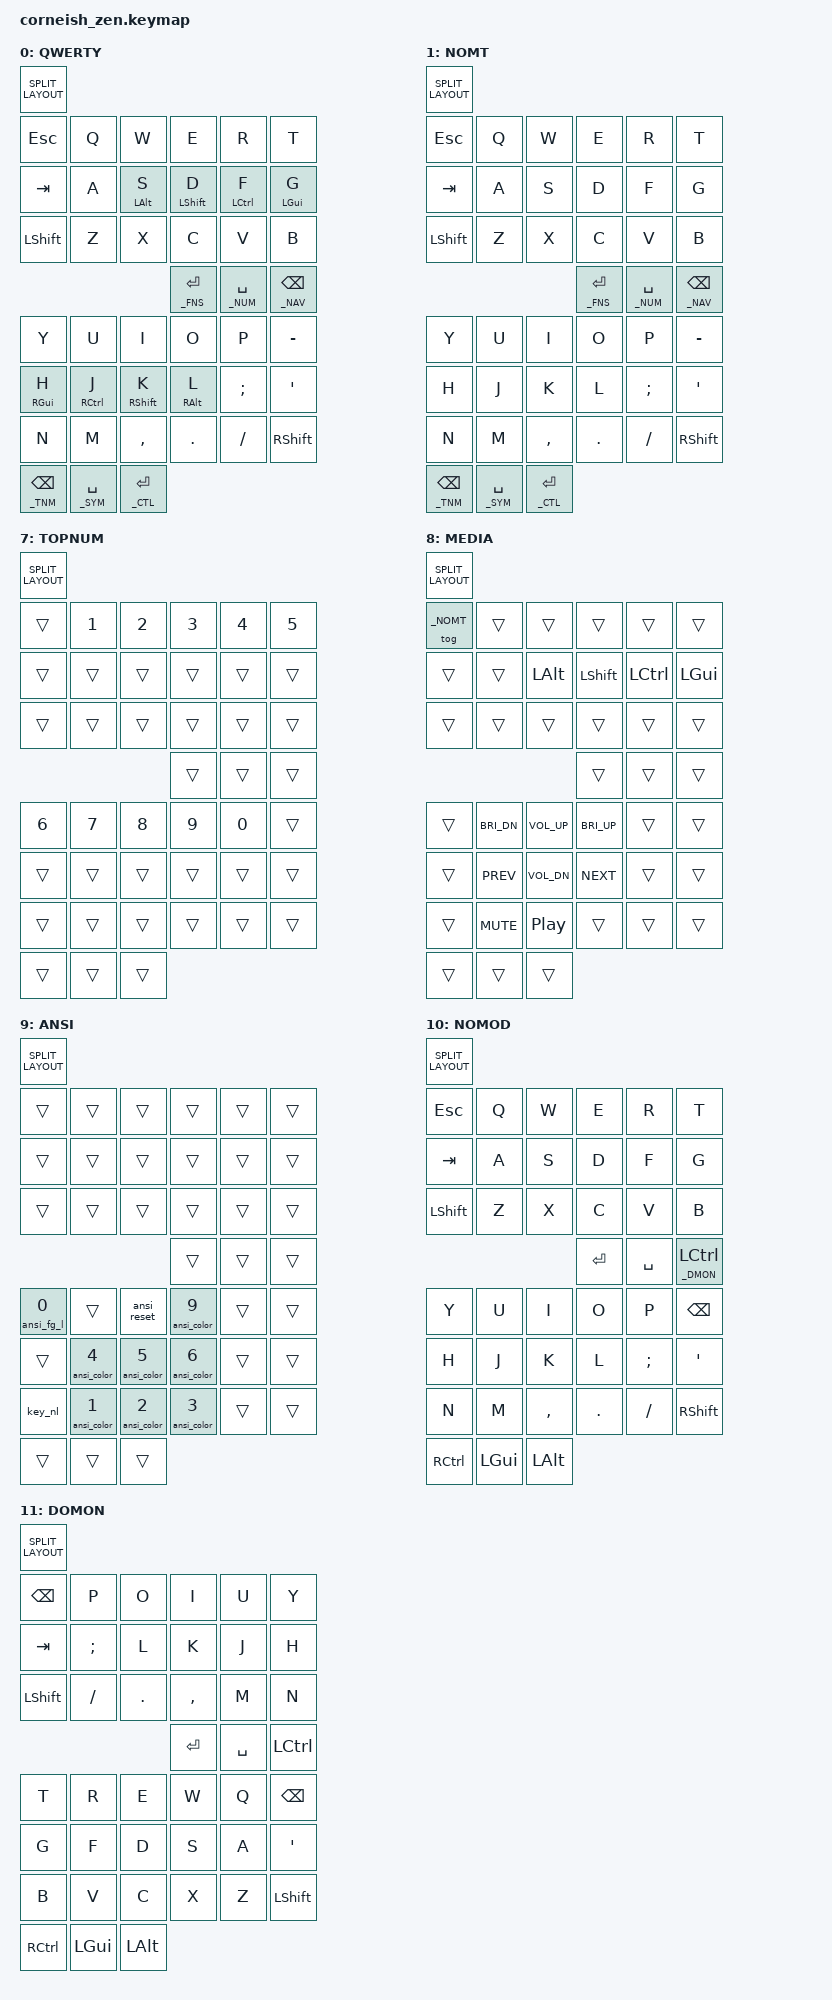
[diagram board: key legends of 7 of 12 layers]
#include <behaviors.dtsi>
#include <dt-bindings/zmk/keys.h>
#include <dt-bindings/zmk/bt.h>
#include <dt-bindings/zmk/outputs.h>

#define _BASE 0
#define _NOMT 1
#define _SYM  2
#define _NUM  3
#define _NAV  4
#define _FNS  5
#define _CTL  6
#define _TNM  7
#define _MED  8
#define _ANSI 9
#define _NOMD 10
#define _DMON 11


#define SPLIT_LAYOUT( \
        K00,    K01,    K02,    K03,    K04,    K05, \
        K06,    K07,    K08,    K09,    K10,    K11, \
        K12,    K13,    K14,    K15,    K16,    K17, \
                                K18,    K19,    K20, \
        \
        K21,    K22,    K23,    K24,    K25,    K26, \
        K27,    K28,    K29,    K30,    K31,    K32, \
        K33,    K34,    K35,    K36,    K37,    K38, \
        K39,    K40,    K41 \
) \
K00  K01  K02  K03  K04  K05    K21  K22  K23  K24  K25  K26 \
K06  K07  K08  K09  K10  K11    K27  K28  K29  K30  K31  K32 \
K12  K13  K14  K15  K16  K17    K33  K34  K35  K36  K37  K38 \
               K18  K19  K20    K39  K40  K41


#define LEFT_LAYER( \
        K00,    K01,    K02,    K03,    K04,    K05, \
        K06,    K07,    K08,    K09,    K10,    K11, \
        K12,    K13,    K14,    K15,    K16,    K17, \
                                K18,    K19,    K20 \
) \
K00  K01  K02  K03  K04  K05    &trans  &trans  &trans  &trans  &trans  &trans \
K06  K07  K08  K09  K10  K11    &trans  &trans  &trans  &trans  &trans  &trans \
K12  K13  K14  K15  K16  K17    &trans  &trans  &trans  &trans  &trans  &trans \
               K18  K19  K20    &trans  &trans  &trans

#define RIGHT_LAYER( \
        K21,    K22,    K23,    K24,    K25,    K26, \
        K27,    K28,    K29,    K30,    K31,    K32, \
        K33,    K34,    K35,    K36,    K37,    K38, \
        K39,    K40,    K41 \
) \
&trans  &trans  &trans  &trans  &trans  &trans    K21  K22  K23  K24  K25  K26 \
&trans  &trans  &trans  &trans  &trans  &trans    K27  K28  K29  K30  K31  K32 \
&trans  &trans  &trans  &trans  &trans  &trans    K33  K34  K35  K36  K37  K38 \
                        &trans  &trans  &trans    K39  K40  K41


#define MIRYOKU_SHIFT_FUNCTION(NAME, BINDING, SHIFT_BINDING) \
/ { \
  behaviors { \
    NAME: NAME { \
      compatible = "zmk,behavior-mod-morph"; \
      label = U_STRINGIFY(NAME); \
      #binding-cells = <0>; \
      bindings = <BINDING>, <SHIFT_BINDING>; \
      mods = <(MOD_LSFT|MOD_RSFT)>; \
    }; \
  }; \
};

&caps_word { continue-list = <UNDERSCORE MINUS BACKSPACE>; };
&lt { quick-tap-ms = <200>; };

/ {
  chosen {
    zmk,matrix_transform = &default_transform;
    //zmk,matrix_transform = &five_column_transform;
  };
};

/ {
        behaviors {
             hm: homerow_mods {
                compatible = "zmk,behavior-hold-tap";
                label = "HOMEROW_MODS";
                #binding-cells = <2>;
                tapping-term-ms = <150>;
                quick-tap-ms = <200>;
                flavor = "balanced";
                require-prior-idle-ms = <50>;
                bindings = <&kp>, <&kp>;
             };

             u_bt_sel_0: u_bt_sel_0 {
                compatible = "zmk,behavior-mod-morph";
                label = "u_bt_sel_0";
                #binding-cells = <0>;
                bindings = <&bt BT_SEL 0>, <&bt BT_DISC 0>;
                mods = <(MOD_LSFT|MOD_RSFT)>;
             };

             u_bt_sel_1: u_bt_sel_1 {
                compatible = "zmk,behavior-mod-morph";
                label = "u_bt_sel_1";
                #binding-cells = <0>;
                bindings = <&bt BT_SEL 1>, <&bt BT_DISC 1>;
                mods = <(MOD_LSFT|MOD_RSFT)>;
             };

             u_bt_sel_2: u_bt_sel_2 {
                compatible = "zmk,behavior-mod-morph";
                label = "u_bt_sel_2";
                #binding-cells = <0>;
                bindings = <&bt BT_SEL 2>, <&bt BT_DISC 2>;
                mods = <(MOD_LSFT|MOD_RSFT)>;
             };

             u_bt_sel_3: u_bt_sel_3 {
                compatible = "zmk,behavior-mod-morph";
                label = "u_bt_sel_3";
                #binding-cells = <0>;
                bindings = <&bt BT_SEL 3>, <&bt BT_DISC 3>;
                mods = <(MOD_LSFT|MOD_RSFT)>;
             };

             u_bt_sel_4: u_bt_sel_4 {
                compatible = "zmk,behavior-mod-morph";
                label = "u_bt_sel_4";
                #binding-cells = <0>;
                bindings = <&bt BT_SEL 4>, <&bt BT_DISC 4>;
                mods = <(MOD_LSFT|MOD_RSFT)>;
             };

             ansi_color: ansi_color {
                compatible = "zmk,behavior-macro-one-param";
                #binding-cells = <1>;
                bindings
                        = <&kp BSLH &kp E &kp LBKT &kp N3>
                        , <&macro_param_1to1>
                        , <&kp MACRO_PLACEHOLDER>
                        , <&kp M>;
             };

             ansi_fg_l: ansi_fg_l {
                compatible = "zmk,behavior-macro-one-param";
                #binding-cells = <1>;
                bindings
                        = <&kp BSLH &kp E &kp LBKT &kp N9>
                        , <&macro_param_1to1>
                        , <&kp MACRO_PLACEHOLDER>
                        , <&kp M>;
             };

             key_nl: key_nl {
                compatible = "zmk,behavior-macro";
                #binding-cells = <0>;
                bindings = <&kp BSLH &kp N>;
             };

             ansi_reset: ansi_reset {
                compatible = "zmk,behavior-macro";
                #binding-cells = <0>;
                bindings = <&kp BSLH &kp E &kp LBKT &kp M>;
             };
        };

        combos {
                compatible = "zmk,combos";
                combo_double_shift_caps_word {
                        timeout-ms = <200>;
                        key-positions = <24 35>;
                        bindings = <&caps_word>;
                };

                combo_toggle_no_home_row_mods {
                        timeout-ms = <200>;
                        key-positions = <0 11>;
                        bindings = <&tog _NOMD>;
                };
        };

        macros {
                ZMK_MACRO(emoji,
                        wait-ms = <30>;
                        tap-ms = <40>;
                        bindings
                                = <&macro_press   &kp LCTRL>
                                , <&macro_press   &kp LGUI>
                                , <&macro_tap     &kp SPACE>
                                , <&macro_release &kp LGUI>
                                , <&macro_release &kp LCTRL>
                                ;
                )
        };

        conditional_layers {
                compatible = "zmk,conditional-layers";
                tri_layer {
                        if-layers = <_NAV _TNM>;
                        then-layer = <_MED>;
                };

                ansi_layer {
                        if-layers = <_NUM _SYM>;
                        then-layer = <_ANSI>;
                };
        };

        keymap {
                compatible = "zmk,keymap";

                default_layer {
                        label = "QWERTY";

                        bindings = < SPLIT_LAYOUT(
  &kp ESC,        &kp Q,          &kp W,          &kp E,          &kp R,          &kp T,
  &kp TAB,   &kp A,          &hm LALT S,     &hm LSHFT D,    &hm LCTRL F,    &hm LGUI G,
  &kp LSHFT,      &kp Z,          &kp X,          &kp C,          &kp V,          &kp B,
                                                  &lt _FNS RET,   &lt _NUM SPACE, &lt _NAV BSPC,

  &kp Y,          &kp U,          &kp I,          &kp O,          &kp P,          &kp MINUS,
  &hm RGUI H,     &hm RCTRL J,    &hm RSHFT K,    &hm RALT L,     &kp SEMI,       &kp SQT,
  &kp N,          &kp M,          &kp COMMA,      &kp DOT,        &kp FSLH,       &kp RSHFT,
  &lt _TNM BSPC,  &lt _SYM SPACE, &lt _CTL RET
                        ) >;
                };

                nomt_layer {
                        label = "NOMT";

                        bindings = < SPLIT_LAYOUT(
  &kp ESC,        &kp Q,          &kp W,          &kp E,          &kp R,          &kp T,
  &kp TAB,   &kp A,          &kp S,     &kp D,    &kp F,    &kp G,
  &kp LSHFT,      &kp Z,          &kp X,          &kp C,          &kp V,          &kp B,
                                                  &lt _FNS RET,   &lt _NUM SPACE, &lt _NAV BSPC,

  &kp Y,          &kp U,          &kp I,          &kp O,          &kp P,          &kp MINUS,
  &kp H,     &kp J,    &kp K,    &kp L,     &kp SEMI,       &kp SQT,
  &kp N,          &kp M,          &kp COMMA,      &kp DOT,        &kp FSLH,       &kp RSHFT,
  &lt _TNM BSPC,  &lt _SYM SPACE, &lt _CTL RET
                        ) >;
                };

                symbol_layer {
                       label = "SYMBOL";

                        bindings = < LEFT_LAYER(
  &kp AMPS,       &kp EXCL,       &kp AT,         &kp LBRC,       &kp RBRC,       &kp PIPE,
  &kp BSLH,       &kp HASH,       &kp DLLR,       &kp LPAR,       &kp RPAR,       &kp GRAVE,
  &trans,         &kp PRCNT,      &kp CARET,      &kp LBKT,       &kp RBKT,       &kp TILDE,
                                                  &trans,         &trans,         &trans
                        ) >;
                };

                numpad_layer {
                        label = "NUMPAD";

                        bindings = < RIGHT_LAYER(
  &kp KP_DIVIDE,  &kp KP_N7,      &kp KP_N8,      &kp KP_N9,      &kp KP_MULTIPLY,&trans,
  &kp KP_EQUAL,   &kp KP_N4,      &kp KP_N5,      &kp KP_N6,      &kp KP_PLUS,    &trans,
  &kp KP_MINUS,   &kp KP_N1,      &kp KP_N2,      &kp KP_N3,      &kp BSLH,       &trans,
  &trans,         &kp KP_N0,      &kp KP_DOT
                        ) >;
                };

                nav_layer {
                        label = "NAV";

                        bindings = < RIGHT_LAYER(
  &kp PG_UP,      &kp HOME,       &kp UP,         &kp END,        &trans,         &kp DEL,
  &kp PG_DN,      &kp LEFT,       &kp DOWN,       &kp RIGHT,      &trans,         &trans,
  &trans,         &trans,         &trans,         &trans,         &trans,         &emoji,
  &trans,         &trans,         &trans
                        ) >;
                };

                fns_layer {
                        label = "FNS";

                        bindings = < RIGHT_LAYER(
  &kp PG_UP,      &kp F7,         &kp F8,         &kp F9,         &kp F11,        &trans,
  &kp PG_DN,      &kp F4,         &kp F5,         &kp F6,         &kp F11,        &trans,
  &trans,         &kp F1,         &kp F2,         &kp F3,         &kp F10,        &trans,
  &trans,         &trans,         &trans
                        ) >;
                };

                control_layer {
                       label = "CONTROL";

                       bindings = < LEFT_LAYER(
  &trans,         &trans,         &trans,         &trans,         &out OUT_TOG,   &bt BT_CLR,
  &trans,         &u_bt_sel_0,    &u_bt_sel_1,    &u_bt_sel_2,    &u_bt_sel_3,    &u_bt_sel_4,
  &trans,         &trans,         &trans,         &trans,         &trans,         &trans,
                                                  &trans,         &trans,         &trans
                        ) >;
                };

                topnum_layer {
                       label = "TOPNUM";

                       bindings = < SPLIT_LAYOUT(
  &trans,         &kp N1,         &kp N2,         &kp N3,         &kp N4,         &kp N5,
  &trans,         &trans,         &trans,         &trans,         &trans,         &trans,
  &trans,         &trans,         &trans,         &trans,         &trans,         &trans,
                                                  &trans,         &trans,         &trans,

  &kp N6,         &kp N7,         &kp N8,         &kp N9,         &kp N0,         &trans,
  &trans,         &trans,         &trans,         &trans,         &trans,         &trans,
  &trans,         &trans,         &trans,         &trans,         &trans,         &trans,
  &trans,         &trans,         &trans
                        ) >;
                };

                media_layer {
                       label = "MEDIA";

                       bindings = < SPLIT_LAYOUT(
  &tog _NOMT,         &trans,         &trans,         &trans,         &trans,         &trans,
  &trans,         &trans,         &kp LALT,         &kp LSHFT,         &kp LCTRL,         &kp LGUI,
  &trans,         &trans,         &trans,         &trans,         &trans,         &trans,
                                                  &trans,         &trans,         &trans,

  &trans,         &kp C_BRI_DN,   &kp C_VOL_UP,   &kp C_BRI_UP,   &trans,         &trans,
  &trans,         &kp C_PREV,     &kp C_VOL_DN,   &kp C_NEXT,     &trans,         &trans,
  &trans,         &kp K_MUTE,     &kp C_PP,       &trans,         &trans,         &trans,
  &trans,         &trans,         &trans
                        ) >;
                };

                ansi_layer {
                       label = "ANSI";

                       bindings = < SPLIT_LAYOUT(
  &trans,         &trans,         &trans,         &trans,         &trans,         &trans,
  &trans,         &trans,         &trans,         &trans,         &trans,         &trans,
  &trans,         &trans,         &trans,         &trans,         &trans,         &trans,
                                                  &trans,         &trans,         &trans,

  &ansi_fg_l N0,  &trans,         &ansi_reset,    &ansi_color N9, &trans,         &trans,
  &trans,         &ansi_color N4, &ansi_color N5, &ansi_color N6, &trans,         &trans,
  &key_nl,        &ansi_color N1, &ansi_color N2, &ansi_color N3, &trans,         &trans,
  &trans,         &trans,         &trans
                        ) >;
                };

                non_homerow_mod_layer {
                       label = "NOMOD";

                       bindings = < SPLIT_LAYOUT(
 &kp ESC,        &kp Q,          &kp W,          &kp E,          &kp R,          &kp T,
 &kp TAB,        &kp A,          &kp S,          &kp D,          &kp F,          &kp G,
 &kp LSHFT,      &kp Z,          &kp X,          &kp C,          &kp V,          &kp B,
                                                 &kp RET,        &kp SPACE,      &lt _DMON LCTRL,

 &kp Y,          &kp U,          &kp I,          &kp O,          &kp P,          &kp BSPC,
 &kp H,          &kp J,          &kp K,          &kp L,          &kp SEMI,       &kp SQT,
 &kp N,          &kp M,          &kp COMMA,      &kp DOT,        &kp FSLH,       &kp RSHFT,
 &kp RCTRL,      &kp LGUI,       &kp LALT
                       ) >;
                };

                non_homerow_mod_reverse_layer {
                       label = "DOMON";

                       bindings = < SPLIT_LAYOUT(
 &kp BSPC,       &kp P,          &kp O,          &kp I,          &kp U,          &kp Y,
 &kp TAB,        &kp SEMI,       &kp L,          &kp K,          &kp J,          &kp H,
 &kp LSHFT,      &kp FSLH,       &kp DOT,        &kp COMMA,      &kp M,          &kp N,
                                                 &kp RET,        &kp SPACE,      &kp LCTRL,

 &kp T,          &kp R,          &kp E,          &kp W,          &kp Q,          &kp BSPC,
 &kp G,          &kp F,          &kp D,          &kp S,          &kp A,          &kp SQT,
 &kp B,          &kp V,          &kp C,          &kp X,          &kp Z,          &kp LSHFT,
 &kp RCTRL,      &kp LGUI,       &kp LALT
                       ) >;
                };

//                 media_layer {
//                        label = "EMPTY_SPLIT";

//                        bindings = < SPLIT_LAYOUT(
//   &trans,         &trans,         &trans,         &trans,         &trans,         &trans,
//   &trans,         &trans,         &trans,         &trans,         &trans,         &trans,
//   &trans,         &trans,         &trans,         &trans,         &trans,         &trans,
//                                                   &trans,         &trans,         &trans,

//   &trans,         &trans,         &trans,         &trans,         &trans,         &trans,
//   &trans,         &trans,         &trans,         &trans,         &trans,         &trans,
//   &trans,         &trans,         &trans,         &trans,         &trans,         &trans,
//   &trans,         &trans,         &trans
//                         ) >;
//                 };
        };
};
